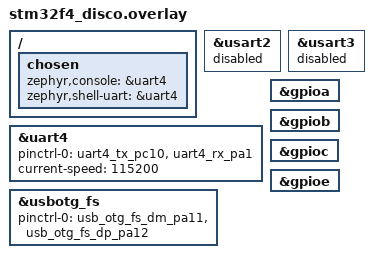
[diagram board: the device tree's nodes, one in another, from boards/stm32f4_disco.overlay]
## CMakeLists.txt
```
cmake_minimum_required(VERSION 3.28.1)

if(BOARD STREQUAL "stm32f4_disco")
    set(DTC_OVERLAY_FILE "${CMAKE_CURRENT_SOURCE_DIR}/boards/stm32f4_disco.overlay")
elseif(BOARD MATCHES "^rpi_pico2")
    set(DTC_OVERLAY_FILE "${CMAKE_CURRENT_SOURCE_DIR}/boards/rpi_pico2.overlay")
elseif(BOARD MATCHES "^rpi_pico$")
    set(DTC_OVERLAY_FILE "${CMAKE_CURRENT_SOURCE_DIR}/boards/rpi_pico.overlay")
endif()

find_package(Zephyr REQUIRED HINTS $ENV{ZEPHYR_BASE})
project(usb_hid_proxy)

# Common source files
target_sources(app PRIVATE
    ${CMAKE_CURRENT_SOURCE_DIR}/src/main.c
    ${CMAKE_CURRENT_SOURCE_DIR}/drivers/ch375/src/ch375.c
    ${CMAKE_CURRENT_SOURCE_DIR}/drivers/ch375/src/ch375_uart.c
    ${CMAKE_CURRENT_SOURCE_DIR}/drivers/ch375/src/ch375_host.c
    ${CMAKE_CURRENT_SOURCE_DIR}/drivers/hid/src/hid_parser.c
    ${CMAKE_CURRENT_SOURCE_DIR}/drivers/hid/src/hid_mouse.c
    ${CMAKE_CURRENT_SOURCE_DIR}/drivers/hid/src/hid_keyboard.c
    ${CMAKE_CURRENT_SOURCE_DIR}/drivers/hid/src/hid_output.c
    ${CMAKE_CURRENT_SOURCE_DIR}/src/usb_hid_proxy.c
    ${CMAKE_CURRENT_SOURCE_DIR}/src/input_patterns.c
)

# Platform-specific UART implementation
if(CONFIG_SOC_SERIES_STM32F4X)

    target_sources(app PRIVATE
        ${CMAKE_CURRENT_SOURCE_DIR}/drivers/ch375/src/ch375_uart_stm32.c
    )
    
    # STM32 LL drivers
    zephyr_library_include_directories(
        ${ZEPHYR_BASE}/modules/hal/stm32/stm32cube/stm32f4xx/drivers/include
        ${ZEPHYR_BASE}/modules/hal/stm32/stm32cube/stm32f4xx/soc
    )
    
elseif(CONFIG_SOC_RP2350A_M33 OR CONFIG_SOC_RP2040)

    target_sources(app PRIVATE
        ${CMAKE_CURRENT_SOURCE_DIR}/drivers/ch375/src/ch375_uart_rp2.c
    )
    
    # RP Pico/Pico 2 PIO support
    zephyr_library_include_directories(
        ${ZEPHYR_BASE}/../modules/hal/rpi_pico/src/rp2_common/hardware_pio/include
        ${ZEPHYR_BASE}/../modules/hal/rpi_pico/src/rp2_common/hardware_clocks/include
        ${ZEPHYR_BASE}/../modules/hal/rpi_pico/src/rp2_common/hardware_gpio/include
        ${ZEPHYR_BASE}/../modules/hal/rpi_pico/src/common/hardware_claim/include
        ${ZEPHYR_BASE}/../modules/hal/rpi_pico/src/rp2_common/pico_base/include
    )
    
else()
    message(FATAL_ERROR "Unsupported platform! Only STM32F4X and RP2XXX are supported.")
endif()

# Common include directories
target_include_directories(app PRIVATE
    ${CMAKE_CURRENT_SOURCE_DIR}/include
    ${CMAKE_CURRENT_SOURCE_DIR}/drivers/hid/include
    ${CMAKE_CURRENT_SOURCE_DIR}/drivers/ch375/include
)
```

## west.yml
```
manifest:
  self:
    path: project
  
  remotes:
    - name: zephyrproject-rtos
      url-base: https://github.com/zephyrproject-rtos
  
  projects:
    - name: zephyr
      remote: zephyrproject-rtos
      revision: v4.2.0
      import: true
```

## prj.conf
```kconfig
# General Configuration
CONFIG_MAIN_STACK_SIZE=4096
CONFIG_SYSTEM_WORKQUEUE_STACK_SIZE=2048
CONFIG_HEAP_MEM_POOL_SIZE=16384

# USB Device Support
CONFIG_USB_DEVICE_STACK=y
CONFIG_USB_DEVICE_HID=y
CONFIG_USB_HID_POLL_INTERVAL_MS=8
CONFIG_USB_HID_BOOT_PROTOCOL=n
CONFIG_USB_DEVICE_REMOTE_WAKEUP=y

# Multiple HID interfaces
CONFIG_USB_COMPOSITE_DEVICE=y
CONFIG_USB_HID_DEVICE_COUNT=2

# USB Device Info
CONFIG_USB_DEVICE_VID=0x1E7D
CONFIG_USB_DEVICE_PID=0x2E7C
CONFIG_USB_DEVICE_MANUFACTURER="Roccat"
CONFIG_USB_DEVICE_PRODUCT="Composite USB HID Device"

CONFIG_LOG=y
CONFIG_BOOT_BANNER=y
CONFIG_EARLY_CONSOLE=y
CONFIG_ASSERT=y

# Print float
CONFIG_CBPRINTF_FP_SUPPORT=y
CONFIG_NEWLIB_LIBC_FLOAT_PRINTF=y

CONFIG_SERIAL=y
CONFIG_PINCTRL=y
```

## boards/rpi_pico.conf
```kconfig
CONFIG_PIO_RPI_PICO=y
CONFIG_UART_RPI_PICO_PIO=y
```

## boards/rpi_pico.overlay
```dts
/*
 * RP2040 and RP2350 share the same peripheral configuration.
 */
#include "rpi_pico2.overlay"
```

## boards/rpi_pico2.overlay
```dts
/ {
    chosen {
        zephyr,console = &uart0;
        zephyr,shell-uart = &uart0;
    };
};

&uart1 {
    status = "disabled";
};

&pio0 {
    compatible = "raspberrypi,pico-pio";
    status = "okay";
    clocks = <&clocks RPI_PICO_CLKID_CLK_SYS>;
    resets = <&reset RPI_PICO_RESETS_RESET_PIO0>;
    #address-cells = <1>;
    #size-cells = <0>;
};

&pio1 {
    compatible = "raspberrypi,pico-pio";
    status = "okay";
    clocks = <&clocks RPI_PICO_CLKID_CLK_SYS>;
    resets = <&reset RPI_PICO_RESETS_RESET_PIO1>;
    #address-cells = <1>;
    #size-cells = <0>;
};

&usbd {
    status = "okay";
};

&gpio0 {
    status = "okay";
};

/ {
    ch375_devices {
        compatible = "gpio-keys";
        
        ch375a_int: ch375a_int {
            gpios = <&gpio0 2 GPIO_ACTIVE_LOW>;
            label = "CH375A INT";
        };
    };
};
```

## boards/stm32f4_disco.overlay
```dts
/ {
    chosen {
        zephyr,console = &uart4;
        zephyr,shell-uart = &uart4;
    };
};

&usart2 {
    status = "disabled";
};

&usart3 {
    status = "disabled";
};

&uart4 {
    pinctrl-0 = <&uart4_tx_pc10 &uart4_rx_pa1>;
    pinctrl-names = "default";
    current-speed = <115200>;
    status = "okay";
};

&usbotg_fs {
    pinctrl-0 = <&usb_otg_fs_dm_pa11 &usb_otg_fs_dp_pa12>;
    pinctrl-names = "default";
    status = "okay";
};

&gpioa {
    status = "okay";
};

&gpiob {
    status = "okay";
};

&gpioc {
    status = "okay";
};

&gpioe {
    status = "okay";
};
```

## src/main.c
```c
/* SPDX-License-Identifier: GPL-3.0-or-later */
/**
 * ╔═══════════════════════════════════════════════════════════════════════╗
 * ║                          GhostHIDe Project                            ║
 * ╚═══════════════════════════════════════════════════════════════════════╝
 * 
 * @file           main.c
 * @brief          Main program entry point and HID device proxy
 * 
 * @author         destrocore
 * @date           2025
 * 
 * @details
 * Main application demonstrating USB HID device enumeration, descriptor
 * parsing, and real-time input forwarding. Manages dual CH375 USB host
 * controllers for mouse and keyboard passthrough.
 * 
 * @copyright 
 * Copyright (c) 2025 akaDestrocore
 * This program is free software: you can redistribute it and/or modify
 * it under the terms of the GNU General Public License as published by
 * the Free Software Foundation, either version 3 of the License, or
 * (at your option) any later version.
 */

#include <zephyr/kernel.h>
#include <zephyr/sys/printk.h>
#include <zephyr/logging/log.h>
#include "ch375.h"
#include "ch375_host.h"
#include "ch375_uart.h"
#include "hid_parser.h"
#include "hid_mouse.h"
#include "usb_hid_proxy.h"
#include "hid_output.h"
#include "hid_keyboard.h"
#include "input_patterns.h"

LOG_MODULE_REGISTER(main, LOG_LEVEL_INF);

/* Defines -------------------------------------------------------------------*/
#define CH375_MODULE_COUNT 2
#define DEFAULT_REPORT_INTERVAL_MS 8
#define MAIN_LOOP_SLEEP_MS 1
#define KEYBOARD_BREAK_TIMEOUT_MS 50
#define ENUMERATION_WAIT_TIMEOUT_MS 10000
#define IFACE_MOUSE     0
#define IFACE_KEYBOARD  1

/* Type Deffinitions ---------------------------------------------------------*/
typedef struct {
    
    const char *name;
    struct gpio_dt_spec intGpio;

    struct ch375_Context_t *ch375Ctx;
    struct USB_Device_t usbDev;
    struct USBHID_Device_t hidDev;
    union {
        struct HID_Mouse_t mouse;
        struct HID_Keyboard_t keyboard;
    };

    bool isConnected;
    uint8_t interfaceNum;

    uint32_t lastReportTimestampMs;
    uint32_t reportIntervalMs;
    
} DeviceInput_t;

/* Private variables ---------------------------------------------------------*/
static DeviceInput_t gDeviceInputs[CH375_MODULE_COUNT];
static struct RecoilComp_Context_t *gRecoilCompCtx = NULL;
static bool gRcEnabled;
static bool gRcActive;

static const char banner[] = 
"                                                                      \n"
" ██████  ██   ██  ██████  ███████ ████████ ██   ██ ██ ██████  ███████ \n"
"██       ██   ██ ██    ██ ██         ██    ██   ██ ██ ██   ██ ██      \n"
"██   ███ ███████ ██    ██ ███████    ██    ███████ ██ ██   ██ █████   \n"
"██    ██ ██   ██ ██    ██      ██    ██    ██   ██ ██ ██   ██ ██      \n"
" ██████  ██   ██  ██████  ███████    ██    ██   ██ ██ ██████  ███████ \n";

/* Private function prototypes -----------------------------------------------*/
static int initCh375Device(DeviceInput_t *pDevIn, const char *pName, 
                            int usartIndex, const struct gpio_dt_spec *pIntGpio, 
                            uint8_t interfaceNum);
static int openDeviceInput(DeviceInput_t *pDevIn);
static void waitAllDevicesConnect(void);
static int openAllDeviceInputs(void);
static void loopHandleDevices(void);
static int handleMouseInput(DeviceInput_t *pDevIn);
static int handleKeyboardInput(DeviceInput_t *pDevIn);
static void closeAllDevices(void);
static int initInputPatterns(void);

/**
  * @brief  The application entry point.
  * @retval int
  */
int main(void)
{
    int ret = -1;

    // Print banner
    printk("%s%s%s", "\x1b[36m", banner, "\x1b[0m");

#if defined(CONFIG_SOC_SERIES_STM32F4X)
    // // Initialize CH375 USB INT pins
    // static const struct gpio_dt_spec ch375aIntGpio = {
    //     .port = DEVICE_DT_GET(DT_NODELABEL(gpioc)),
    //     .pin = 13,
    //     .dt_flags = GPIO_ACTIVE_LOW
    // };

    // static const struct gpio_dt_spec ch375bIntGpio = {
    //     .port = DEVICE_DT_GET(DT_NODELABEL(gpioc)),
    //     .pin = 14,
    //     .dt_flags = GPIO_ACTIVE_LOW
    // };

    // const struct device *gpio_dev = DEVICE_DT_GET(DT_NODELABEL(gpioc));
    // if (!device_is_ready(gpio_dev)) {
    //     LOG_ERR("GPIO C not ready!");
    //     return -1;
    // }

#elif defined(CONFIG_SOC_RP2350A_M33) || defined(CONFIG_SOC_RP2040)

    // Verify GPIO is ready
    // const struct device *gpio_dev = DEVICE_DT_GET(DT_NODELABEL(gpio0));
    // if (!device_is_ready(gpio_dev)) {
    //     LOG_ERR("GPIO not ready!");
    //     return -1;
    // }

#else
    #error "Unsupported platform"
#endif

    // Initialize CH375 USB host controllers
    ret = initCh375Device(&gDeviceInputs[0], "CH375A", CH375_A_USART_INDEX, NULL, IFACE_MOUSE);
    if (0 != ret) {
        return ret;
    }

    ret = initCh375Device(&gDeviceInputs[1], "CH375B", CH375_B_USART_INDEX, NULL, IFACE_KEYBOARD);
    if (0 != ret) {
        return ret;
    }

    while (1) {
        LOG_INF("Waiting for USB devices...");
        waitAllDevicesConnect();

        LOG_INF("Enumerating devices...");
        ret = openAllDeviceInputs();
        if (ret < 0) {
            LOG_ERR("[ FAILED ] Failed to enumerate devices");
            k_msleep(1000);
            continue;
        }

        LOG_INF("Initializing recoil compensation patterns...");
        ret = initInputPatterns();
        if (ret < 0) {
            LOG_ERR("[ FAILED ] Pattern init failed: %d", ret);
            k_msleep(1000);
            continue;
        }

        LOG_INF("Initializing USB device output...");
        ret = usbhid_proxyInit();
        if (USBHID_SUCCESS != ret) {
            LOG_ERR("[ FAILED ] USB HID proxy initialization failed: %d", ret);
            recoilComp_close(gRecoilCompCtx);
            gRecoilCompCtx = NULL;
            k_msleep(1000);
            continue;
        }

        LOG_INF("Waiting for USB enumeration...");
        int enumerationAttempts = 0;
        while (true != usbhid_proxyIsReady() && enumerationAttempts < 100) {
            k_msleep(100);
            enumerationAttempts++;
        }

        if (true != usbhid_proxyIsReady()) {
            LOG_ERR("USB enumeration timeout");
            usbhid_proxyCleanup();
            closeAllDevices();
            recoilComp_close(gRecoilCompCtx);
            gRecoilCompCtx = NULL;
            k_msleep(1000);
            continue;
        }

        LOG_INF("[ OK ] USB ready - starting forwarding");
        loopHandleDevices();

        LOG_WRN("Device disconnected, restarting...");
        usbhid_proxyCleanup();
        recoilComp_close(gRecoilCompCtx);
        gRecoilCompCtx = NULL;
        closeAllDevices();
        k_msleep(1000);
    }
    
    return 0;
}

/**
 * @brief Initialize CH375 USB host controller
 * @param pDevIn Pointer to device input structure
 * @param pName Device name for logging
 * @param usartIndex Hardware USART index
 * @param pIntGpio GPIO interrupt pin specification (NULL for polling mode)
 * @param interfaceNum USB interface number (0=mouse, 1=keyboard)
 * @return 0 on success, negative error code otherwise
 */
static int initCh375Device(DeviceInput_t *pDevIn, const char *pName, int usartIndex, const struct gpio_dt_spec *pIntGpio, uint8_t interfaceNum) {
    
    int ret = -1;

    pDevIn->name = pName;
    pDevIn->interfaceNum = interfaceNum;
    
    // Store INT GPIO (NULL for polling mode)
    if (NULL != pIntGpio) {
        pDevIn->intGpio = *pIntGpio;
    } else {
        LOG_INF("%s: Running in POLLING MODE", pName);
        memset(&pDevIn->intGpio, 0, sizeof(pDevIn->intGpio));
    }
    
    pDevIn->lastReportTimestampMs = 0;
    pDevIn->reportIntervalMs = DEFAULT_REPORT_INTERVAL_MS;
    pDevIn->isConnected = false;

    ret = ch375_hwInitManual(pName, usartIndex, pIntGpio, CH375_DEFAULT_BAUDRATE, &pDevIn->ch375Ctx);
    if (ret < 0) {
        LOG_ERR("[ FAILED ] %s: Hardware init failed: %d", pName, ret);
        return ret;
    }

    ret = ch375_hostInit(pDevIn->ch375Ctx, CH375_WORK_BAUDRATE);
    if (CH375_HOST_SUCCESS != ret) {
        LOG_ERR("[ FAILED ] %s: CH375 host init failed: %d", pName, ret);
        return -EIO;
    }

    ret = ch375_hwSetBaudrate(pDevIn->ch375Ctx, CH375_WORK_BAUDRATE);
    if (ret < 0) {
        LOG_ERR("%s: Baudrate switch failed: %d", pName, ret);
        return ret;
    }

    LOG_INF("[ OK ] %s: Initialized successfully!", pName);
    return 0;
}

/**
 * @brief Open and enumerate USB HID device
 * @param pDevIn Device input structure
 * @return 0 on success, negative error code otherwise
 */
static int openDeviceInput(DeviceInput_t *pDevIn) {
    
    int ret = -1;

    LOG_INF("%s: Opening USB device...", pDevIn->name);

    ret = ch375_hostUdevOpen(pDevIn->ch375Ctx, &pDevIn->usbDev);
    if (CH375_HOST_SUCCESS != ret) {
        LOG_ERR("%s: Failed to open USB device: %d", pDevIn->name, ret);
        return CH375_HOST_ERROR;
    }

    LOG_INF("[ OK ] %s: USB device opened (VID:PID = %04X:%04X)",
            pDevIn->name, pDevIn->usbDev.vendor_id, pDevIn->usbDev.product_id);

    ret = USBHID_open(&pDevIn->usbDev, 0, &pDevIn->hidDev);
    if (USBHID_SUCCESS != ret) {
        LOG_ERR("[ FAILED ] %s: Failed to open USBHID: %d", pDevIn->name, ret);
        ch375_hostUdevClose(&pDevIn->usbDev);
        return USBHID_ERROR;
    }

    pDevIn->reportIntervalMs = DEFAULT_REPORT_INTERVAL_MS;

    if (USBHID_TYPE_MOUSE == pDevIn->hidDev.hid_type) {
        ret = hidMouse_Open(&pDevIn->hidDev, &pDevIn->mouse);
        if (USBHID_SUCCESS != ret) {
            LOG_ERR("[ FAILED ] %s: Failed to open mouse: %d", pDevIn->name, ret);
            USBHID_close(&pDevIn->hidDev);
            ch375_hostUdevClose(&pDevIn->usbDev);
            return USBHID_ERROR;
        }
        LOG_INF("[ OK ] %s: Mouse opened", pDevIn->name);
    } 
    else if (USBHID_TYPE_KEYBOARD == pDevIn->hidDev.hid_type) {
        ret = hidKeyboard_Open(&pDevIn->hidDev, &pDevIn->keyboard);
        if (USBHID_SUCCESS != ret) {
            LOG_ERR("[ FAILED ] %s: Failed to open keyboard: %d", pDevIn->name, ret);
            USBHID_close(&pDevIn->hidDev);
            ch375_hostUdevClose(&pDevIn->usbDev);
            return -1;
        }
        LOG_INF("[ OK ] %s: Keyboard opened", pDevIn->name);
    } 
    else {
        LOG_ERR("[ FAILED ] %s: Unsupported HID type: %d", pDevIn->name, pDevIn->hidDev.hid_type);
        USBHID_close(&pDevIn->hidDev);
        ch375_hostUdevClose(&pDevIn->usbDev);
        return -1;
    }

    return 0;
}

/**
 * @brief Wait for all configured USB devices to connect
 * @note Blocks until all devices are connected
 */
static void waitAllDevicesConnect(void) {
    
    int ret = -1;
    bool allConnected = false;

    while (1) {
        allConnected = true;

        for (int i = 0; i < CH375_MODULE_COUNT; i++) {
            DeviceInput_t *pDevIn = &gDeviceInputs[i];

            if (true == pDevIn->isConnected) {
                continue;
            }

            // 500ms timeout
            ret = ch375_hostWaitDeviceConnect(pDevIn->ch375Ctx, 500);
            if (CH375_HOST_SUCCESS == ret) {
                LOG_INF("[ OK ] %s: Device connected", pDevIn->name);
                pDevIn->isConnected = true;
            } 
            else if (CH375_HOST_ERROR == ret) {
                LOG_ERR("[ FAILED ] %s: Error waiting for device", pDevIn->name);
                allConnected = false;
            } else {
                allConnected = false;
            }
        }

        if (true == allConnected) {
            break;
        }

        k_msleep(100);
    }

    LOG_INF("[ OK ] All devices connected!");
}

/**
 * @brief Enumerate all connected USB devices
 * @return 0 on success, negative error code on failure
 */
static int openAllDeviceInputs(void) {
    
    int ret = -1;

    for (int i = 0; i < CH375_MODULE_COUNT; i++) {
        ret = openDeviceInput(&gDeviceInputs[i]);
        if (ret < 0) {
            LOG_ERR("[ FAILED ] %s: Failed to enumerate", gDeviceInputs[i].name);
            return ret;
        }
        gDeviceInputs[i].isConnected = true;
    }

    return 0;
}

/**
 * @brief Main HID input forwarding loop
 * @note Runs until device disconnection is detected
 */
static void loopHandleDevices(void) {
    
    int ret = -1;

    LOG_INF("HID processing loop started");

    while (1) {
        for (int i = 0; i < CH375_MODULE_COUNT; i++) {
            DeviceInput_t *pDevIn = &gDeviceInputs[i];

            if (true != pDevIn->isConnected) {
                continue;
            }

            if (USBHID_TYPE_MOUSE == pDevIn->hidDev.hid_type) {
                ret = handleMouseInput(pDevIn);

                if (USBHID_NO_DEV == ret) {
                    LOG_ERR("%s: Device disconnected", pDevIn->name);
                    return;
                }
            }

            else if (USBHID_TYPE_KEYBOARD == pDevIn->hidDev.hid_type) {
                ret = handleKeyboardInput(pDevIn);

                if (USBHID_NO_DEV == ret) {
                    LOG_ERR("%s: Device disconnected", pDevIn->name);
                    return;
                }
            }
        }

        k_msleep(MAIN_LOOP_SLEEP_MS);
    }
}

/**
 * @brief Handle mouse input and forward to USB output
 * @param pDevIn Device input structure
 * @return 0 on success, USBHID_NO_DEV on disconnection, negative on error
 */
static int handleMouseInput(DeviceInput_t *pDevIn) {
    
    int ret = -1;
    uint32_t buttonVal = 0;
    bool needSend = false;

    // Fetch new report from device
    ret = hidMouse_FetchReport(&pDevIn->mouse);
    if (USBHID_NO_DEV == ret) {
        LOG_ERR("%s: Device disconnected", pDevIn->name);
        return ret;
    }

    // Check LMB state
    hidMouse_GetButton(&pDevIn->mouse, HID_MOUSE_BUTTON_LEFT, &buttonVal, false);
    if (0 != buttonVal) {
        // Start/continue compensation if pressed
        if  (true != gRcActive) {
            gRcActive = true;
            recoilComp_restart(gRecoilCompCtx);
            LOG_INF("[ OK ] Recoil compensation ENABLED.");
        }

        // Get compensaton if ready
        if (true == gRcEnabled) {
            struct PatternCompensation_t compData;
            ret = recoilComp_getNextData(gRecoilCompCtx, &compData);

            if (0 == ret) {
                int32_t mouseX;
                int32_t mouseY;
                int32_t finalX;
                int32_t finalY;

                // Get actual mouse movement
                hidMouse_GetOrientation(&pDevIn->mouse, HID_MOUSE_AXIS_X, &mouseX, false);
                hidMouse_GetOrientation(&pDevIn->mouse, HID_MOUSE_AXIS_Y, &mouseY, false);

                finalX = mouseX + compData.x;
                finalY = mouseY + compData.y;

                // Apply compensation
                hidMouse_SetOrientation(&pDevIn->mouse, HID_MOUSE_AXIS_X, finalX, false);
                hidMouse_SetOrientation(&pDevIn->mouse, HID_MOUSE_AXIS_Y, finalY, false);

                needSend = true;
            } else {
                // Just forward mouse data
                needSend = (USBHID_SUCCESS == hidMouse_FetchReport(&pDevIn->mouse)) ? true : false;
            }
        } else {
            // Compensation disabled - just forward as is
            needSend = (USBHID_SUCCESS == ret) ? true : false;
        }
    } else {
        // LMB released
        if ( true == gRcActive) {
            gRcActive = false;
            LOG_INF("[ OK ] Recoil compensation DISABLED");
        }

        needSend = (USBHID_SUCCESS == ret) ? true : false;
    }

    // Send report if we have data
    if (true == needSend) {
        ret = hidOutput_sendMouseReport(&pDevIn->mouse);
        if (USBHID_SUCCESS != ret) {
            LOG_WRN("%s: Failed to send report: %d", pDevIn->name, ret);
        }
    }

    return 0;
}

/**
 * @brief Handle keyboard input and forward to USB output
 * @param pDevIn Device input structure
 * @return 0 on success, USBHID_NO_DEV on disconnection, negative on error
 */
static int handleKeyboardInput(DeviceInput_t *pDevIn) {
    
    int ret = -1;
    struct USBHID_Device_t *pHidDev;
    uint8_t *pReportBuff;
    size_t reportLen;
    uint32_t value;

    static uint8_t lastSentReport[8] = {0};
    static uint8_t lastKeyboardReport[8] = {0};

    pHidDev = pDevIn->keyboard.hid_dev;
    reportLen = pHidDev ? pHidDev->report_len : 0;

    // Fetch new report
    ret = hidKeyboard_FetchReport(&pDevIn->keyboard);

    if (USBHID_NO_DEV == ret) {
        return USBHID_NO_DEV;
    }

    // No new data
    if (USBHID_SUCCESS != ret) {
        return 0;
    }

    // Get report buffer
    ret = USBHID_getReportBuffer(pHidDev, &pReportBuff, NULL, false);
    if (USBHID_SUCCESS != ret || NULL == pReportBuff) {
        return 0;
    }

    // Skip if no chnages
    if (memcmp(pReportBuff, lastKeyboardReport, reportLen) == 0) {
        return 0;
    }

    memcpy(lastKeyboardReport, pReportBuff, reportLen);

    // Process ctrl keys
    hidKeyboard_GetKey(&pDevIn->keyboard, HID_KEY_PAGEUP, &value, false);
    if (0 != value) {
        gRcEnabled = true;
        LOG_INF("Recoil compensation profile ACTIVATED");
    }

    hidKeyboard_GetKey(&pDevIn->keyboard, HID_KEY_PAGEDOWN, &value, false);
    if (0 != value) {
        gRcEnabled = false;
        LOG_INF("Recoil compensation profile DEACTIVATED");
    }

    hidKeyboard_GetKey(&pDevIn->keyboard, HID_KBD_NUMBER('1'), &value, false);
    if (0 != value) {
        int res = recoilComp_setPreset(gRecoilCompCtx, TEMPLATE_OW2_SOLDIER76);
        if (0 == res) {
            LOG_INF("[ OK ] Selected: SOLDIER 76");
        }
    }

    hidKeyboard_GetKey(&pDevIn->keyboard, HID_KBD_NUMBER('2'), &value, false);
    if (0 != value) {
        int res = recoilComp_setPreset(gRecoilCompCtx, TEMPLATE_OW2_CASSIDY);
        if (0 == res) {
            LOG_INF("[ OK ] Selected: CASSIDY");
        }
    }

    // Coefficient adjustment
    hidKeyboard_GetKey(&pDevIn->keyboard, HID_KEY_EQUAL, &value, false);
    if (0 != value) {
        recoilComp_changeCoefficient(gRecoilCompCtx, true);
    }

    hidKeyboard_GetKey(&pDevIn->keyboard, HID_KEY_MINUS, &value, false);
    if (0 != value) {
        recoilComp_changeCoefficient(gRecoilCompCtx, false);
    }

    // Sensitivity adjustment
    hidKeyboard_GetKey(&pDevIn->keyboard, HID_KEY_COMMA, &value, false);
    if (0 != value) {
        recoilComp_changeSensitivity(gRecoilCompCtx, true);
    }

    hidKeyboard_GetKey(&pDevIn->keyboard, HID_KEY_DOT, &value, false);
    if (0 != value) {
        recoilComp_changeSensitivity(gRecoilCompCtx, false);
    }

    // Forward to USB output
    ret = usbhid_proxySendReport(pDevIn->interfaceNum, pReportBuff, reportLen);

    if (0 == ret) {
        memcpy(lastSentReport, pReportBuff, reportLen);
    } else {
        LOG_ERR("Keyboard send failed: %d", ret);
    }

    return 0;
}

/**
 * @brief Close all open USB devices and free resources
 */
static void closeAllDevices(void) {
    
    for (int i = 0; i < CH375_MODULE_COUNT; i++) {
        DeviceInput_t* pDevIn = &gDeviceInputs[i];

        if (USBHID_TYPE_MOUSE == pDevIn->hidDev.hid_type) {
            hidMouse_Close(&pDevIn->mouse);
        } 
        
        else if (USBHID_TYPE_KEYBOARD == pDevIn->hidDev.hid_type) {
            hidKeyboard_Close(&pDevIn->keyboard);
        }

        USBHID_close(&pDevIn->hidDev);
        ch375_hostUdevClose(&pDevIn->usbDev);

        pDevIn->isConnected = false;
    }
}

/**
 * @brief Initialize Recoil Compensation
 * @return 0 on success, negative error code otherwise
 */
static int initInputPatterns(void) {
    
    int ret = recoilComp_open(&gRecoilCompCtx);
    if (ret < 0) {
        LOG_ERR("[ FAILED ] Failed to open compensation pattern context: %d", ret);
        return ret;
    }

    gRcEnabled = false;
    gRcActive = false;

    LOG_INF("[ OK ] Recoil compensation pattern initialized");
    return 0;
}
```

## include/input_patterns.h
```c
/* SPDX-License-Identifier: GPL-3.0-or-later */
/**
 * ╔═══════════════════════════════════════════════════════════════════════╗
 * ║                          GhostHIDe Project                            ║
 * ╚═══════════════════════════════════════════════════════════════════════╝
 * 
 * @file           input_patterns.h
 * @brief          Dynamic modification of HID data with specific patterns
 * 
 * @author         destrocore
 * @date           2025
 * 
 * @details
 * Provides recoil compensation. Each recoil patterns that are compensated through
 * mouse movement adjustments.
 * 
 * @copyright 
 * Copyright (c) 2025 akaDestrocore
 * This program is free software: you can redistribute it and/or modify
 * it under the terms of the GNU General Public License as published by
 * the Free Software Foundation, either version 3 of the License, or
 * (at your option) any later version.
 */

#ifndef INPUT_PATTERNS_H
#define INPUT_PATTERNS_H

#ifdef __cplusplus
extern "C" {
#endif

#include <zephyr/kernel.h>
#include <zephyr/logging/log.h>
#include <math.h>
#include <stdlib.h>
#include <string.h>

/* Macros -------------------------------------------------------------------*/
#define USB_REPORT_INTERVAL             8
#define RECOIL_COMP_DEFAULT_COEFF       1.0f
#define RECOIL_COMP_DEFAULT_SENS        2.5f
#define RECOIL_COMP_COEFF_MIN           0.1f
#define RECOIL_COMP_COEFF_MAX           10.0f
#define RECOIL_COMP_PRESET_COUNT        3
#define RECOIL_COMP_DATA_GROUP_SIZE     3
#define RECOIL_COMP_SENS_MIN            0.1f
#define RECOIL_COMP_SENS_MAX            100.0f
#define RECOIL_COMP_COEFF_STEP          0.1f
#define RECOIL_COMP_SENS_STEP           0.1f

/* Type Definitions ---------------------------------------------------------*/
/**
 * @brief Pattern Presets
 */
typedef enum {
    TEMPLATE_NONE,
    TEMPLATE_OW2_SOLDIER76,
    TEMPLATE_OW2_CASSIDY
} PatternPreset_e;

/**
 * @brief Context state flags
 */
typedef enum {
    RECOIL_COMP_STATE_UNINITIALIZED     = 0,
    RECOIL_COMP_STATE_INITIALIZED       = 1,
    RECOIL_COMP_STATE_PRESET_ACTIVE     = 2,
    RECOIL_COMP_STATE_ARRAYS_ALLOCATED  = 4
} RecoilCompState_e;

/**
 * @brief Recoil data collection structure
 */
typedef struct {
    const float* pData;
    int dataLen;
    int firerounds_sampling;
} PresetCollection_t;

/**
 * @brief Compensation axes X and Y
 */
struct PatternCompensation_t {
    int32_t x;
    int32_t y;
};

/**
 * @brief Recoil compensation context structure
 */
struct RecoilComp_Context_t {
    float coefficient;
    float sensitivity;
    uint32_t stateFlags;

    // Preset data
    const PresetCollection_t* pCollect;
    int32_t* pX;
    int32_t* pY;
    int32_t* pTs;
    int arrLen;

    // Sequence state
    int arrIndex;
    uint32_t lastTickMs;

    struct k_mutex lock;
};

/**
 * @brief Initialize recoil compensation context
 */
int recoilComp_open(struct RecoilComp_Context_t** ppCtx);

/**
 * @brief Close recoil compensation context
 */
void recoilComp_close(struct RecoilComp_Context_t* pCtx);

/**
 * @brief Restart recoil compensation sequence
 */
int recoilComp_restart(struct RecoilComp_Context_t* pCtx);

/**
 * @brief Get next compensated movement data
 */
int recoilComp_getNextData(struct RecoilComp_Context_t* pCtx, struct PatternCompensation_t* pData);

/**
 * @brief Set current preset and load compensation profile
 */
int recoilComp_setPreset(struct RecoilComp_Context_t* pCtx, uint32_t presetIndex);

/**
 * @brief Adjust compensation strength
 */
int recoilComp_changeCoefficient(struct RecoilComp_Context_t* pCtx, bool isAdd);

/**
 * @brief Adjust compensation sensitivity
 */
int recoilComp_changeSensitivity(struct RecoilComp_Context_t* pCtx, bool isAdd);

#ifdef __cplusplus
}
#endif

#endif /* INPUT_PATTERNS_H */
```

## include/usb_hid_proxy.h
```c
/* SPDX-License-Identifier: GPL-3.0-or-later */
/**
 * ╔═══════════════════════════════════════════════════════════════════════╗
 * ║                          GhostHIDe Project                            ║
 * ╚═══════════════════════════════════════════════════════════════════════╝
 * 
 * @file           usb_hid_proxy.h
 * @brief          USB HID proxy for composite mouse + keyboard interfaces
 * 
 * @author         destrocore
 * @date           2025
 * 
 * @details
 * USB HID proxy implementing a composite HID device exposing separate mouse 
 * and keyboard interfaces. This module:
 *  - Registers standard HID report descriptors for a multi-button mouse 
 *      (8-button, 16-bit X/Y, 8-bit wheel) and a standard 6-key keyboard
 * 
 * - Binds to Zephyr HID device instances ("HID_0" and "HID_1"), registers 
 *      descriptors and initializes the HID class devices.
 * 
 * - Provides a thread-safe send API (USB_HID_proxySendReport) using semaphores
 *      that start at 1 to coordinate endpoint writes and the INT callbacks
 * 
 * @copyright 
 * Copyright (c) 2025 akaDestrocore
 * This program is free software: you can redistribute it and/or modify
 * it under the terms of the GNU General Public License as published by
 * the Free Software Foundation, either version 3 of the License, or
 * (at your option) any later version.
 */

#ifndef HID_PROXY_H
#define HID_PROXY_H

#include <zephyr/kernel.h>
#include <zephyr/device.h>
#include <zephyr/usb/usb_device.h>
#include <zephyr/usb/class/usb_hid.h>
#include <zephyr/logging/log.h>
#include <stddef.h>
#include <stdint.h>
#include <stdbool.h>

#ifdef __cplusplus
extern "C" {
#endif

/**
 * @brief Initialize USB HID
 */
int usbhid_proxyInit(void);

/**
 * @brief Send HID report
 */
int usbhid_proxySendReport(uint8_t ifaceNum, uint8_t *pReport, size_t len);

/**
 * @brief USB disable and reset of globals and semaphopres
 */
void usbhid_proxyCleanup(void);

/**
 * @brief Public API to check if USB is ready for writes
 */
bool usbhid_proxyIsReady(void);

#ifdef __cplusplus
}
#endif

#endif /* HID_PROXY_H */
```

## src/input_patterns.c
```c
/* SPDX-License-Identifier: GPL-3.0-or-later */
/**
 * ╔═══════════════════════════════════════════════════════════════════════╗
 * ║                          GhostHIDe Project                            ║
 * ╚═══════════════════════════════════════════════════════════════════════╝
 * 
 * @file           input_patterns.с
 * @brief          Dynamic modification of HID data with specific patterns implementation
 * 
 * @author         destrocore
 * @date           2025
 * 
 * @details
 * Implements recoil compensation.
 * 
 * @copyright 
 * Copyright (c) 2025 akaDestrocore
 * This program is free software: you can redistribute it and/or modify
 * it under the terms of the GNU General Public License as published by
 * the Free Software Foundation, either version 3 of the License, or
 * (at your option) any later version.
 */

#include "input_patterns.h"

LOG_MODULE_REGISTER(input_patterns, LOG_LEVEL_INF);

/**
 * @brief Soldier 76 recoil pattern
 * {x_offset, y_offset, time_ms}
 */
static const float gRawPreset_OW2_Soldier76[] = {
    +0.00000, +0.00000, 111,
    +0.00000, -1.45500, 111,
    +0.00000, +0.47045, 111,
    +0.00000, -1.36901, 111,
    +0.00000, +0.44265, 111,
    +0.00000, -0.85873, 111,
    +0.00000, +0.41649, 111,
    +0.00000, -0.80798, 111,
    +0.00000, +0.39187, 111,
    +0.00000, -0.38012, 111,
    +0.00000, +0.36871, 111,
    +0.00000, -0.35765, 111,
    +0.00000, +0.34692, 111,
    +0.00000, -0.33651, 111,
    +0.00000, +0.32642, 111,
    +0.00000, -0.18998, 111,
    +0.00000, +0.18428, 111,
    +0.00000, +0.00000, 111,
    +0.00000, +0.17339, 111,
    +0.00000, +0.00000, 111,
    +0.00000, +0.00000, 111,
    +0.00000, +0.00000, 111,
    +0.00000, +0.00000, 111,
    +0.00000, +0.00000, 111,
    +0.00000, +0.00000, 111,
    +0.00000, +0.00000, 111,
    +0.00000, +0.00000, 111,
    +0.00000, +0.00000, 111,
    +0.00000, +0.00000, 111,
    +0.00000, +0.00000, 111,
};

/**
 * @brief Cassidy preset recoil pattern
 */
static const float gRawPreset_OW2_Cassidy[] = {
    +0.00000, +0.00000, 50,
    +0.00000, -20.20000, 150,
    +0.00000, +0.00000, 300,
    +0.00000, +0.00000, 50,
    +0.00000, -20.20000, 150,
    +0.00000, +0.00000, 300,
    +0.00000, +0.00000, 50,
    +0.00000, -20.20000, 150,
    +0.00000, +0.00000, 300,
    +0.00000, +0.00000, 50,
    +0.00000, -20.20000, 150,
    +0.00000, +0.00000, 300,
    +0.00000, +0.00000, 50,
    +0.00000, -20.20000, 150,
    +0.00000, +0.00000, 300,
    +0.00000, +0.00000, 50,
    +0.00000, -20.20000, 150,
    +0.00000, +0.00000, 300,
};

static const PresetCollection_t sRecoilCollectArr[RECOIL_COMP_PRESET_COUNT] = {
    
    {
        .pData = NULL,
        .dataLen = 0,
        .firerounds_sampling = 0,
    },

    {
        .pData = gRawPreset_OW2_Soldier76,
        .dataLen = ARRAY_SIZE(gRawPreset_OW2_Soldier76),
        .firerounds_sampling = round(111/USB_REPORT_INTERVAL),
    },

    {
        .pData = gRawPreset_OW2_Cassidy,
        .dataLen = ARRAY_SIZE(gRawPreset_OW2_Cassidy),
        .firerounds_sampling = round(500/USB_REPORT_INTERVAL),
    },
};

/* Private Function Prototypes ------------------------------------------------*/
static void recoilComp_cbFreeLocked(struct RecoilComp_Context_t* pCtx);
static uint32_t recoilComp_cbTimeElapsed(uint32_t start, uint32_t now);
static int recoilComp_cbGenerateDataLocked(struct RecoilComp_Context_t* pCtx);

/**
 * @brief Initialize recoil compensation context
 * @param ppCtx Pointer to context pointer for output
 * @return 0 on success, negative error code otherwise
 */
int recoilComp_open(struct RecoilComp_Context_t** ppCtx) {
    
    struct RecoilComp_Context_t* pNewCtx;

    if (NULL == ppCtx) {
        return -EINVAL;
    }

    pNewCtx = k_malloc(sizeof(struct RecoilComp_Context_t));
    if (NULL == pNewCtx) {
        LOG_ERR("Failed to allocate space for new context");
        return -ENOMEM;
    }

    memset(pNewCtx, 0x00, sizeof(struct RecoilComp_Context_t));
    k_mutex_init(&pNewCtx->lock);

    pNewCtx->coefficient = RECOIL_COMP_DEFAULT_COEFF;
    pNewCtx->sensitivity = RECOIL_COMP_DEFAULT_SENS;
    pNewCtx->stateFlags = RECOIL_COMP_STATE_INITIALIZED;

    *ppCtx = pNewCtx;

    LOG_INF("[ OK ] Recoil compensation context initialized");
    return 0;
}

/**
 * @brief Close recoil compensation context and free resources
 * @param pCtx Pointer to context
 */
void recoilComp_close(struct RecoilComp_Context_t* pCtx) {

    if (NULL == pCtx) {
        return;
    }

    k_mutex_lock(&pCtx->lock, K_FOREVER);
    recoilComp_cbFreeLocked(pCtx);
    pCtx->stateFlags = RECOIL_COMP_STATE_UNINITIALIZED;
    k_mutex_unlock(&pCtx->lock);

    k_free(pCtx);
}

/**
 * @brief Restart recoil compensation
 * @param pCtx Pointer to context
 * @return 0 on success, negative error code otherwise
 */
int recoilComp_restart(struct RecoilComp_Context_t* pCtx) {

    if (NULL == pCtx) {
        return -EINVAL;
    }

    k_mutex_lock(&pCtx->lock, K_FOREVER);

    // Not initialized
    if (0 == (pCtx->stateFlags & RECOIL_COMP_STATE_INITIALIZED)) {
        k_mutex_unlock(&pCtx->lock);
        LOG_ERR("Context not initialized");
        return -EINVAL;
    }

    if (0 == (pCtx->stateFlags & RECOIL_COMP_STATE_PRESET_ACTIVE)) {
        k_mutex_unlock(&pCtx->lock);
        LOG_ERR("Preset not selected.");
        return -EINVAL;
    }

    pCtx->lastTickMs = k_uptime_get_32();
    pCtx->arrIndex = 0;

    k_mutex_unlock(&pCtx->lock);

    return 0;
}

/**
 * @brief Get next compensated movement data
 * @param pCtx Pointer to context
 * @param pData Pointer to output data structure
 * @return 0 if data available, error code otherwise
 */
int recoilComp_getNextData(struct RecoilComp_Context_t* pCtx, struct PatternCompensation_t* pData) {

    int ret = -1;
    uint32_t now = 0;
    uint32_t elapsed = 0;

    if (NULL == pCtx || NULL == pData) {
        return -EINVAL;
    }

    k_mutex_lock(&pCtx->lock, K_FOREVER);

    if (0 == (pCtx->stateFlags & RECOIL_COMP_STATE_INITIALIZED)) {
        k_mutex_unlock(&pCtx->lock);
        return -EINVAL;
    }

    if (0 == (pCtx->stateFlags & RECOIL_COMP_STATE_ARRAYS_ALLOCATED)) {
        k_mutex_unlock(&pCtx->lock);
        return -EINVAL;
    }

    // Check if sequence is complete
    if (pCtx->arrIndex >= pCtx->arrLen) {
        k_mutex_unlock(&pCtx->lock);
        return -1;
    }

    now = k_uptime_get_32();
    elapsed = recoilComp_cbTimeElapsed(pCtx->lastTickMs, now);

    // Check if time has passed for next shot
    if (elapsed >= (uint32_t)pCtx->pTs[pCtx->arrIndex]) {
        pCtx->lastTickMs += (uint32_t)pCtx->pTs[pCtx->arrIndex];

        pData->x = pCtx->pX[pCtx->arrIndex];
        pData->y = -1 * pCtx->pY[pCtx->arrIndex];

        pCtx->arrIndex++;
        ret = 0;
    } else {
        ret = -1;
    }

    k_mutex_unlock(&pCtx->lock);
    
    return ret;
}

/**
 * @brief Set current preset and load compensation profile
 * @param pCtx Pointer to context
 * @param presetIndex Preset enum value
 * @return 0 on success, error code otherwise
 */
int recoilComp_setPreset(struct RecoilComp_Context_t* pCtx, uint32_t presetIndex) {
    
    int ret = -1;

    if (NULL == pCtx) {
        return -EINVAL;
    }

    if (presetIndex >= RECOIL_COMP_PRESET_COUNT) {
        LOG_ERR("Invalid preset index: %u", presetIndex);
        return -EINVAL;
    }

    k_mutex_lock(&pCtx->lock, K_FOREVER);

    if (0 == (pCtx->stateFlags & RECOIL_COMP_STATE_INITIALIZED)) {
        k_mutex_unlock(&pCtx->lock);
        LOG_ERR("Context not initialized");
        return -EINVAL;
    }

    // Free old data
    recoilComp_cbFreeLocked(pCtx);

    // Set new collection
    pCtx->pCollect = &sRecoilCollectArr[presetIndex];

    // Generate new data
    ret = recoilComp_cbGenerateDataLocked(pCtx);
    if (ret < 0) {
        pCtx->pCollect = NULL;
        LOG_ERR("Failed to generate recoil data: %d", ret);
        k_mutex_unlock(&pCtx->lock);
        return ret;
    }

    pCtx->stateFlags |= RECOIL_COMP_STATE_PRESET_ACTIVE;
    k_mutex_unlock(&pCtx->lock);

    LOG_INF("Preset active: %u", presetIndex);
    return 0;
}

/**
 * @brief Adjust compensation coefficient
 * @param pCtx Pointer to context
 * @param isAdd true to increase, false to decrease
 * @return 0 on success, error code otherwise
 */
int recoilComp_changeCoefficient(struct RecoilComp_Context_t* pCtx, bool isAdd) {
    
    if (NULL == pCtx) {
        return -EINVAL;
    }

    k_mutex_lock(&pCtx->lock, K_FOREVER);

    if (0 == (pCtx->stateFlags & RECOIL_COMP_STATE_INITIALIZED)) {
        k_mutex_unlock(&pCtx->lock);
        return -EINVAL;
    }

    pCtx->coefficient = CLAMP(pCtx->coefficient + (isAdd ? RECOIL_COMP_COEFF_STEP : -RECOIL_COMP_COEFF_STEP), 
                                                                RECOIL_COMP_COEFF_MIN, RECOIL_COMP_COEFF_MAX);

    if (pCtx->stateFlags & RECOIL_COMP_STATE_PRESET_ACTIVE) {
        recoilComp_cbFreeLocked(pCtx);
        int ret = recoilComp_cbGenerateDataLocked(pCtx);
        if (ret < 0) {
            LOG_ERR("Failed to regenerate compensation data: %d", ret);
        } else {
            LOG_INF("Compensation data regenerated successfully");
        }
    }

    LOG_INF("Coefficient: %.2f", (double)pCtx->coefficient);
    k_mutex_unlock(&pCtx->lock);

    return 0;
}

/**
 * @brief Adjust compensation sensitivity
 * @param pCtx Pointer to context
 * @param isAdd true to increase, false to decrease
 * @return 0 on success, negative error code otherwise
 */
int recoilComp_changeSensitivity(struct RecoilComp_Context_t* pCtx, bool isAdd) {

    if (NULL == pCtx) {
        return -EINVAL;
    }

    k_mutex_lock(&pCtx->lock, K_FOREVER);

    if (0 == (pCtx->stateFlags & RECOIL_COMP_STATE_INITIALIZED)) {
        k_mutex_unlock(&pCtx->lock);
        return -EINVAL;
    }

    pCtx->sensitivity = CLAMP( pCtx->sensitivity + (isAdd ? RECOIL_COMP_SENS_STEP : -RECOIL_COMP_SENS_STEP), 
                                                                RECOIL_COMP_SENS_MIN, RECOIL_COMP_SENS_MAX);

    if (pCtx->stateFlags & RECOIL_COMP_STATE_PRESET_ACTIVE) {
        recoilComp_cbFreeLocked(pCtx);
        int ret = recoilComp_cbGenerateDataLocked(pCtx);
        if (ret < 0) {
            LOG_ERR("Failed to regenerate compensation data: %d", ret);
        } else {
            LOG_INF("Compensation data regenerated successfully");
        }
    }

    LOG_INF("Sensitivity: %.2f", (double)pCtx->sensitivity);
    k_mutex_unlock(&pCtx->lock);
    
    return 0;
}

/* --------------------------------------------------------------------------
 * HELPER FUNCTIONS
 * -------------------------------------------------------------------------*/
static void recoilComp_cbFreeLocked(struct RecoilComp_Context_t* pCtx) {
    // Lock must be held by caller
    if (NULL != pCtx->pX) {
        k_free(pCtx->pX);
        pCtx->pX = NULL;
    }

    if (NULL != pCtx->pY) {
        k_free(pCtx->pY);
        pCtx->pY = NULL;
    }

    if (NULL != pCtx->pTs) {
        k_free(pCtx->pTs);
        pCtx->pTs = NULL;
    }

    pCtx->arrLen = 0;
    pCtx->arrIndex = 0;
    pCtx->stateFlags &= ~RECOIL_COMP_STATE_ARRAYS_ALLOCATED;
}

static uint32_t recoilComp_cbTimeElapsed(uint32_t start, uint32_t now) {
    
    if (now >= start) {
        return now - start;
    }

    return (0xFFFFFFFF - start) + now + 1;
}

static int recoilComp_cbGenerateDataLocked(struct RecoilComp_Context_t* pCtx) {
    
    int ret = -1;
    const PresetCollection_t* pColl;
    int rawIdx = 0;
    int idx = 0;
    int i = 0;
    int j = 0;
    int groups = 0;
    float x = 0;
    float y = 0;
    float timestamp = 0;
    float sensitivity = 0;
    int32_t sX = 0;
    int32_t sY = 0;
    int32_t sTimestamp = 0; 
    int32_t fixX = 0; 
    int32_t fixY = 0; 
    int32_t fixTs = 0;
    float sumX = 0;
    float sumY = 0;
    float sumTs = 0;
    float sumX0 = 0;
    float sumY0 = 0;
    float sumTs0 = 0;

    if (NULL == pCtx) {
        return -EINVAL;
    }

    pColl = pCtx->pCollect;
    if (NULL == pColl) {
        LOG_ERR("Invalid collection data");
        return -EINVAL;
    }

    if (NULL == pColl->pData) {
        LOG_ERR("Invalid collection data");
        return -EINVAL;
    }

    if ((pColl->dataLen <= 0) || (0 != (pColl->dataLen % RECOIL_COMP_DATA_GROUP_SIZE))) {
        LOG_ERR("Invalid collection data");
        return -EINVAL;
    }

    if (pColl->firerounds_sampling <= 0) {
        LOG_ERR("Invalid collection data");
        return -EINVAL;
    }

    // Clamp parameters
    pCtx->coefficient = CLAMP(pCtx->coefficient, RECOIL_COMP_COEFF_MIN, RECOIL_COMP_COEFF_MAX);
    pCtx->sensitivity = CLAMP(pCtx->sensitivity, RECOIL_COMP_SENS_MIN, RECOIL_COMP_SENS_MAX);

    sensitivity = pCtx->sensitivity;
    groups = pColl->dataLen / RECOIL_COMP_DATA_GROUP_SIZE;
    pCtx->arrLen = pColl->firerounds_sampling * groups;

    // Allocate arrays
    pCtx->pX = k_malloc(sizeof(int32_t) * pCtx->arrLen);
    if (NULL == pCtx->pX) {
        LOG_ERR("Failed to allocate X array");
        return -ENOMEM;
    }

    pCtx->pY = k_malloc(sizeof(int32_t) * pCtx->arrLen);
    if (NULL == pCtx->pY) {
        LOG_ERR("Failed to allocate Y array");
        k_free(pCtx->pX);
        pCtx->pX = NULL;
        return -ENOMEM;
    }

    pCtx->pTs = k_malloc(sizeof(int32_t) * pCtx->arrLen);
    if (NULL == pCtx->pTs) {
        k_free(pCtx->pX);
        k_free(pCtx->pY);
        pCtx->pX = NULL;
        pCtx->pY = NULL;
        LOG_ERR("Failed to allocate timestamp array");
        return -ENOMEM;
    }

    // Generate data with error correction for rounding
    for (i = 0; i < groups; i++) {
        rawIdx = i * RECOIL_COMP_DATA_GROUP_SIZE;

        x = pColl->pData[rawIdx + 0] * pCtx->coefficient / sensitivity;
        y = pColl->pData[rawIdx + 1] * pCtx->coefficient / sensitivity;
        timestamp = pColl->pData[rawIdx + 2];

        sX = (int32_t)floorf( x / (float)pColl->firerounds_sampling);
        sY = (int32_t)floorf( y / (float)pColl->firerounds_sampling);
        sTimestamp = (int32_t)floorf( timestamp / (float)pColl->firerounds_sampling);

        sumX += sX * pColl->firerounds_sampling;
        sumY += sY * pColl->firerounds_sampling;
        sumTs += sTimestamp * pColl->firerounds_sampling;
        sumX0 += x;
        sumY0 += y;
        sumTs0 += timestamp;

        fixX = (int32_t)roundf(sumX0 - sumX);
        fixY = (int32_t)roundf(sumY0 - sumY);
        fixTs = (int32_t)roundf(sumTs0 - sumTs);

        for (j = 0; j < pColl->firerounds_sampling; j++) {
            
            if (idx >= pCtx->arrLen) {
                break;
            }

            pCtx->pX[idx] = sX;
            pCtx->pY[idx] = sY;
            pCtx->pTs[idx] = sTimestamp;

            if (fixX > 0) {
                pCtx->pX[idx]++;
                sumX++;
                fixX--;
            }

            if (fixY > 0) {
                pCtx->pY[idx]++;
                sumY++;
                fixY--;
            }

            if (fixTs > 0) {
                pCtx->pTs[idx]++;
                sumTs++;
                fixTs--;
            }

            idx++;
        }
    }

    pCtx->stateFlags |= RECOIL_COMP_STATE_ARRAYS_ALLOCATED;

    return 0;
}
```
